# RL6955_IP_SVD register map
Vendor: Realtek
Registers are 32-bit, read-write, reset 0x0 unless marked. A register's access mark holds for its fields unless they carry their own. Offsets are from the block's base; [hi:lo] are bit positions.

## AES_KEY_REG
Base 0x400C3000
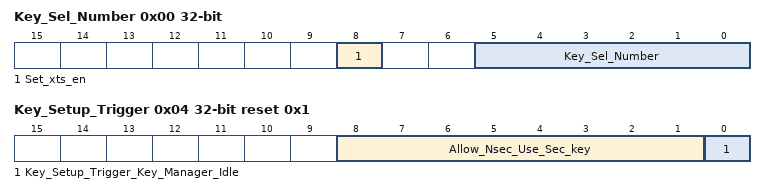
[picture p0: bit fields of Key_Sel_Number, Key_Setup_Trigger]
0x00 Key_Sel_Number — Key Selection Number Register
  [8] Set_xts_en — Only available when SUPPORT_XTS_MODE = 1. When this bit is set to 1, the trigger will write the selected key to xts_key2. Otherwise, the trigger will write the selected key to key/xts_key1.
  [5:0] Key_Sel_Number — The key number determines which key to use in the key setting. HW keys: 0~31, the number can be used is determined by the number of HW keys configured. Hardwired key: 32, if enabled Secure SW key: 33 Shared SW key: 34~ , the number can be used is determined by the number of SW keys configured.
0x04 Key_Setup_Trigger access per field reset 0x1 — Key Setup Process Trigger Register
  [8:1] Allow_Nsec_Use_Sec_key ro — When setting this field to 1, allow non-secure domain to trigger the secure key. Only secure domain can write this bit. The corresponding bits will be numbered from smallest to largest. For example, the number of the secure domain key is 0, 1, 33. Bits 0, 1, 2 control key0, key1, key33 respectively.
  [0] Key_Setup_Trigger_Key_Manager_Idle rw — Write 1 to trigger key setup process If the selected key is a hardware key, assert hw_key_req and wait for hw_key_ack. The key setup process will not start until hw_key_ack is received. The key managment unit uses the APB interface to pass the key into the engine according to the selected key. The read data represents whether the engine is idle or not. 0: Key setup process ongoing 1: Key setup is completed After triggering the key setup process, read this bit to confirm completion.
0x10 Secure_key0_7 — Secure key0 Register[255:224]
  [31:0] Secure_Key0_7 — Secure key0 register[32*7+31:31*7]
0x14 Secure_key0_6 — Secure key0 Register[223:192]
  [31:0] Secure_Key0_6 — Secure key0 register[32*6+31:31*6]
0x18 Secure_key0_5 — Secure key0 Register[191:160]
  [31:0] Secure_Key0_5 — Secure key0 register[32*5+31:31*5]
0x1C Secure_key0_4 — Secure key0 Register[159:128]
  [31:0] Secure_Key0_4 — Secure key0 register[32*4+31:31*4]
0x20 Secure_key0_3 — Secure key0 Register[127:96]
  [31:0] Secure_Key0_3 — Secure key0 register[32*3+31:31*3]
0x24 Secure_key0_2 — Secure key0 Register[95:64]
  [31:0] Secure_Key0_2 — Secure key0 register[32*2+31:31*2]
0x28 Secure_key0_1 — Secure key0 Register[63:32]
  [31:0] Secure_Key0_1 — Secure key0 register[32*1+31:31*1]
0x2C Secure_key0_0 — Secure key0 Register[31:0]
  [31:0] Secure_Key0_0 — Secure key0 register[32*0+31:31*0]
0x30 Secure_key1_7 — Secure key1 Register[255:224]
  [31:0] Secure_Key1_7 — Secure key1 register[32*7+31:31*7]
0x34 Secure_key1_6 — Secure key1 Register[223:192]
  [31:0] Secure_Key1_6 — Secure key1 register[32*6+31:31*6]
0x38 Secure_key1_5 — Secure key1 Register[191:160]
  [31:0] Secure_Key1_5 — Secure key1 register[32*5+31:31*5]
0x3C Secure_key1_4 — Secure key1 Register[159:128]
  [31:0] Secure_Key1_4 — Secure key1 register[32*4+31:31*4]
0x40 Secure_key1_3 — Secure key1 Register[127:96]
  [31:0] Secure_Key1_3 — Secure key1 register[32*3+31:31*3]
0x44 Secure_key1_2 — Secure key1 Register[95:64]
  [31:0] Secure_Key1_2 — Secure key1 register[32*2+31:31*2]
0x48 Secure_key1_1 — Secure key1 Register[63:32]
  [31:0] Secure_Key1_1 — Secure key1 register[32*1+31:31*1]
0x4C Secure_key1_0 — Secure key1 Register[31:0]
  [31:0] Secure_Key1_0 — Secure key1 register[32*0+31:31*0]
0x50 Shared_key0_7 — Shared key0 Register[255:224]
  [31:0] Shared_Key0_7 — Shared key0 register[32*7+31:32*7]
0x54 Shared_key0_6 — Shared key0 Register[223:192]
  [31:0] Shared_Key0_6 — Shared key0 register[32*6+31:32*6]
0x58 Shared_key0_5 — Shared key0 Register[191:160]
  [31:0] Shared_Key0_5 — Shared key0 register[32*5+31:32*5]
0x5C Shared_key0_4 — Shared key0 Register[159:128]
  [31:0] Shared_Key0_4 — Shared key0 register[32*4+31:32*4]
0x60 Shared_key0_3 — Shared key0 Register[127:96]
  [31:0] Shared_Key0_3 — Shared key0 register[32*3+31:32*3]
0x68 Shared_key0_2 — Shared key0 Register[95:64]
  [31:0] Shared_Key0_2 — Shared key0 register[32*2+31:32*2]
0x68 Shared_key0_1 — Shared key0 Register[63:32]
  [31:0] Shared_Key0_1 — Shared key0 register[32*1+31:32*1]
0x6C Shared_key0_0 — Shared key0 Register[31:0]
  [31:0] Shared_Key0_0 — Shared key0 register[32*0+31:32*0]
0x70 Shared_key1_7 — Shared key1 Register[255:224]
  [31:0] Shared_key1_7 — Shared key1 register[32*7+31:32*7]
0x74 Shared_key1_6 — Shared key1 Register[223:192]
  [31:0] Shared_key1_6 — Shared key1 register[32*6+31:32*6]
0x78 Shared_key1_5 — Shared key1 Register[191:160]
  [31:0] Shared_key1_5 — Shared key1 register[32*5+31:32*5]
0x7C Shared_key1_4 — Shared key1 Register[159:128]
  [31:0] Shared_key1_4 — Shared key1 register[32*4+31:32*4]
0x80 Shared_key1_3 — Shared key1 Register[127:96]
  [31:0] Shared_key1_3 — Shared key1 register[32*3+31:32*3]
0x88 Shared_key1_2 — Shared key1 Register[95:64]
  [31:0] Shared_key1_2 — Shared key1 register[32*2+31:32*2]
0x88 Shared_key1_1 — Shared key1 Register[63:32]
  [31:0] Shared_key1_1 — Shared key1 register[32*1+31:32*1]
0x8C Shared_key1_0 — Shared key1 Register[31:0]
  [31:0] Shared_key1_0 — Shared key1 register[32*0+31:32*0]
